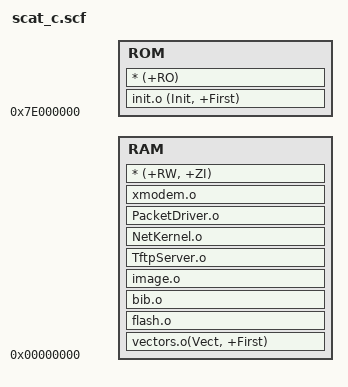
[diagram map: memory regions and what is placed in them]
;/******************************************************************************
; *
; * Copyright (c) 2003 Windond Electronics Corp.
; * All rights reserved.
; *
; * $Workfile: $
; *
; * $Author: $
; ******************************************************************************/
;/*
; * $History: $
; */
; This scatter loading setting is for W90N740.
; After booting, the ROM was remapped to 0x7E000000 and SDRAM was 
; initialized. Remapping and SDRAM initialization were done by init.s
; Ater the init.s exected, it pass the control right to __main.o of C Library.
; The __main.o would copy vector table and RO codes to memory according to the 
; scatter loading setting.
; 
; NOTE: The heap base of C Library is defined in retarget.c.
;       It is needed to be set for C Library.

ROM_LOAD 0x7E000000
{
    ROM +0
    {
        init.o (Init, +First)
        * (+RO)
        
    }
    RAM 0x0
    {
        vectors.o(Vect, +First)
        flash.o
        bib.o
        image.o
        TftpServer.o
        NetKernel.o
        PacketDriver.o
        xmodem.o
        * (+RW, +ZI)
    }

}

